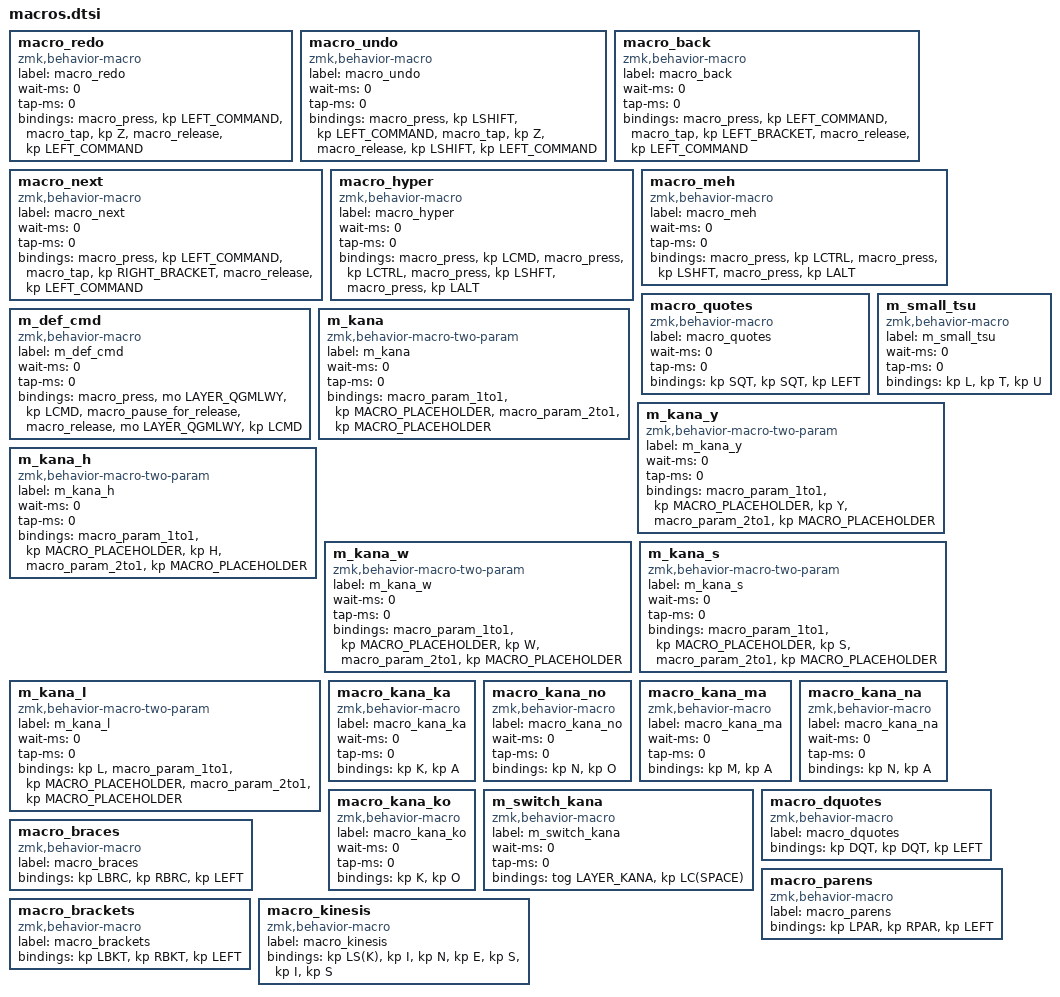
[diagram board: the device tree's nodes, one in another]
macro_redo: macro_redo {
  compatible = "zmk,behavior-macro";
  label = "macro_redo";
  wait-ms = <0>;
  tap-ms = <0>;
  #binding-cells = <0>;
  bindings = <&macro_press &kp LEFT_COMMAND>, <&macro_tap &kp Z>, <&macro_release &kp LEFT_COMMAND>;
};
macro_undo: macro_undo {
  compatible = "zmk,behavior-macro";
  label = "macro_undo";
  wait-ms = <0>;
  tap-ms = <0>;
  #binding-cells = <0>;
  bindings = <&macro_press &kp LSHIFT &kp LEFT_COMMAND>, <&macro_tap &kp Z>, <&macro_release &kp LSHIFT &kp LEFT_COMMAND>;
};
macro_back: macro_back {
  compatible = "zmk,behavior-macro";
  label = "macro_back";
  wait-ms = <0>;
  tap-ms = <0>;
  #binding-cells = <0>;
  bindings = <&macro_press &kp LEFT_COMMAND>, <&macro_tap &kp LEFT_BRACKET>, <&macro_release &kp LEFT_COMMAND>;
};
macro_next: macro_next {
  compatible = "zmk,behavior-macro";
  label = "macro_next";
  wait-ms = <0>;
  tap-ms = <0>;
  #binding-cells = <0>;
  bindings = <&macro_press &kp LEFT_COMMAND>, <&macro_tap &kp RIGHT_BRACKET>, <&macro_release &kp LEFT_COMMAND>;
};
macro_hyper: macro_hyper {
  compatible = "zmk,behavior-macro";
  label = "macro_hyper";
  wait-ms = <0>;
  tap-ms = <0>;
  #binding-cells = <0>;
  bindings = <&macro_press &kp LCMD>, <&macro_press &kp LCTRL>, <&macro_press &kp LSHFT>, <&macro_press &kp LALT>;
};
macro_meh: macro_meh {
  compatible = "zmk,behavior-macro";
  label = "macro_meh";
  wait-ms = <0>;
  tap-ms = <0>;
  #binding-cells = <0>;
  bindings = <&macro_press &kp LCTRL>, <&macro_press &kp LSHFT>, <&macro_press &kp LALT>;
};
macro_quotes: macro_quotes {
  compatible = "zmk,behavior-macro";
  label = "macro_quotes";
  wait-ms = <0>;
  tap-ms = <0>;
  #binding-cells = <0>;
  bindings = <&kp SQT>, <&kp SQT>, <&kp LEFT>;
};

m_small_tsu: m_small_tsu {
  compatible = "zmk,behavior-macro";
  label = "m_small_tsu";
  wait-ms = <0>;
  tap-ms = <0>;
  #binding-cells = <0>;
  bindings = <&kp L>, <&kp T>, <&kp U>;
};

m_def_cmd: m_def_cmd {
  compatible = "zmk,behavior-macro";
  label = "m_def_cmd";
  wait-ms = <0>;
  tap-ms = <0>;
  #binding-cells = <0>;
  bindings = <&macro_press &mo LAYER_QGMLWY &kp LCMD>, <&macro_pause_for_release>, <&macro_release &mo LAYER_QGMLWY &kp LCMD>;
};

m_kana: m_kana {
  compatible = "zmk,behavior-macro-two-param";
  label = "m_kana";
  wait-ms = <0>;
  tap-ms = <0>;
  #binding-cells = <2>;
  bindings = <&macro_param_1to1>, <&kp MACRO_PLACEHOLDER>, <&macro_param_2to1>, <&kp MACRO_PLACEHOLDER>;
};

m_kana_y: m_kana_y {
  compatible = "zmk,behavior-macro-two-param";
  label = "m_kana_y";
  wait-ms = <0>;
  tap-ms = <0>;
  #binding-cells = <2>;
  bindings = <&macro_param_1to1>, <&kp MACRO_PLACEHOLDER>, <&kp Y>, <&macro_param_2to1>, <&kp MACRO_PLACEHOLDER>;
};
m_kana_h: m_kana_h {
  compatible = "zmk,behavior-macro-two-param";
  label = "m_kana_h";
  wait-ms = <0>;
  tap-ms = <0>;
  #binding-cells = <2>;
  bindings = <&macro_param_1to1>, <&kp MACRO_PLACEHOLDER>, <&kp H>, <&macro_param_2to1>, <&kp MACRO_PLACEHOLDER>;
};
m_kana_w: m_kana_w {
  compatible = "zmk,behavior-macro-two-param";
  label = "m_kana_w";
  wait-ms = <0>;
  tap-ms = <0>;
  #binding-cells = <2>;
  bindings = <&macro_param_1to1>, <&kp MACRO_PLACEHOLDER>, <&kp W>, <&macro_param_2to1>, <&kp MACRO_PLACEHOLDER>;
};
m_kana_s: m_kana_s {
  compatible = "zmk,behavior-macro-two-param";
  label = "m_kana_s";
  wait-ms = <0>;
  tap-ms = <0>;
  #binding-cells = <2>;
  bindings = <&macro_param_1to1>, <&kp MACRO_PLACEHOLDER>, <&kp S>, <&macro_param_2to1>, <&kp MACRO_PLACEHOLDER>;
};
m_kana_l: m_kana_l {
  compatible = "zmk,behavior-macro-two-param";
  label = "m_kana_l";
  wait-ms = <0>;
  tap-ms = <0>;
  #binding-cells = <2>;
  bindings = <&kp L>, <&macro_param_1to1>, <&kp MACRO_PLACEHOLDER>, <&macro_param_2to1>, <&kp MACRO_PLACEHOLDER>;
};


macro_kana_ka: macro_kana_ka {
  compatible = "zmk,behavior-macro";
  label = "macro_kana_ka";
  #binding-cells = <0>;
  wait-ms = <0>;
  tap-ms = <0>;
  bindings = <&kp K>, <&kp A>;
};
macro_kana_no: macro_kana_no {
  compatible = "zmk,behavior-macro";
  label = "macro_kana_no";
  wait-ms = <0>;
  tap-ms = <0>;
  #binding-cells = <0>;
  bindings = <&kp N>, <&kp O>;
};
macro_kana_ma: macro_kana_ma {
  compatible = "zmk,behavior-macro";
  label = "macro_kana_ma";
  wait-ms = <0>;
  tap-ms = <0>;
  #binding-cells = <0>;
  bindings = <&kp M>, <&kp A>;
};
macro_kana_na: macro_kana_na {
  compatible = "zmk,behavior-macro";
  label = "macro_kana_na";
  wait-ms = <0>;
  tap-ms = <0>;
  #binding-cells = <0>;
  bindings = <&kp N>, <&kp A>;
};
macro_kana_ko: macro_kana_ko {
  compatible = "zmk,behavior-macro";
  label = "macro_kana_ko";
  wait-ms = <0>;
  tap-ms = <0>;
  #binding-cells = <0>;
  bindings = <&kp K>, <&kp O>;
};

m_switch_kana: m_switch_kana {
  compatible = "zmk,behavior-macro";
  label = "m_switch_kana";
  wait-ms = <0>;
  tap-ms = <0>;
  #binding-cells = <0>;
  bindings = <&tog LAYER_KANA>, <&kp LC(SPACE)>;
};

macro_dquotes: macro_dquotes{
compatible = "zmk,behavior-macro";
label = "macro_dquotes";
#binding-cells = <0>;
bindings = <&kp DQT>, <&kp DQT>, <&kp LEFT>;
};
macro_braces: macro_braces{
compatible = "zmk,behavior-macro";
label = "macro_braces";
#binding-cells = <0>;
bindings = <&kp LBRC>, <&kp RBRC>, <&kp LEFT>;
};
macro_parens: macro_parens{
compatible = "zmk,behavior-macro";
label = "macro_parens";
#binding-cells = <0>;
bindings = <&kp LPAR>, <&kp RPAR>, <&kp LEFT>;
};
macro_brackets: macro_brackets{
compatible = "zmk,behavior-macro";
label = "macro_brackets";
#binding-cells = <0>;
bindings = <&kp LBKT>, <&kp RBKT>, <&kp LEFT>;
};
macro_kinesis: macro_kinesis{
compatible = "zmk,behavior-macro";
label = "macro_kinesis";
#binding-cells = <0>;
bindings = <&kp LS(K)>, <&kp I>, <&kp N>, <&kp E>, <&kp S>, <&kp I>, <&kp S>;
};
